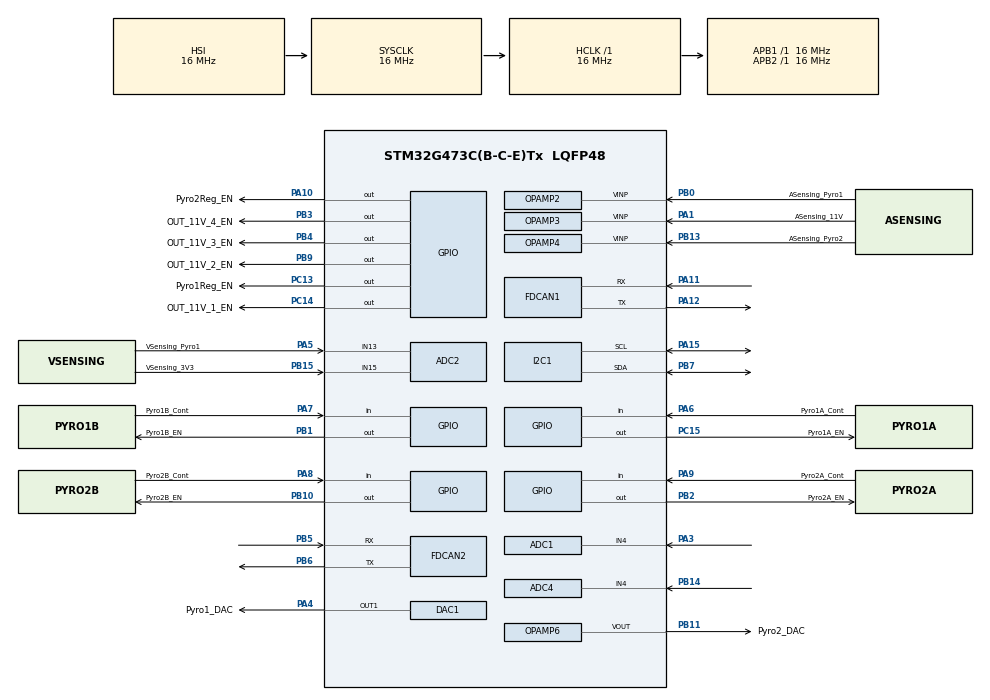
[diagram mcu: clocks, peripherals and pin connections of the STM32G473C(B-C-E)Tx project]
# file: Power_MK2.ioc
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ADC1.Channel-0\#ChannelRegularConversion=ADC_CHANNEL_4
ADC1.NbrOfConversion=1
ADC1.NbrOfConversionFlag=1
ADC1.OffsetNumber-0\#ChannelRegularConversion=ADC_OFFSET_NONE
ADC1.Rank-0\#ChannelRegularConversion=1
ADC1.SamplingTime-0\#ChannelRegularConversion=ADC_SAMPLETIME_2CYCLES_5
ADC1.master=1
ADC2.Channel-0\#ChannelRegularConversion=ADC_CHANNEL_13
ADC2.NbrOfConversionFlag=1
ADC2.OffsetNumber-0\#ChannelRegularConversion=ADC_OFFSET_NONE
ADC2.Rank-0\#ChannelRegularConversion=1
ADC2.SamplingTime-0\#ChannelRegularConversion=ADC_SAMPLETIME_2CYCLES_5
ADC4.Channel-2\#ChannelRegularConversion=ADC_CHANNEL_4
ADC4.NbrOfConversionFlag=1
ADC4.OffsetNumber-2\#ChannelRegularConversion=ADC_OFFSET_NONE
ADC4.Rank-2\#ChannelRegularConversion=1
ADC4.SamplingTime-2\#ChannelRegularConversion=ADC_SAMPLETIME_2CYCLES_5
FDCAN1.AutoRetransmission=ENABLE
FDCAN1.CalculateBaudRateNominal=1000000
FDCAN1.CalculateTimeBitNominal=1000
FDCAN1.CalculateTimeQuantumNominal=62.5
FDCAN1.FrameFormat=FDCAN_FRAME_FD_NO_BRS
FDCAN1.NominalPrescaler=2
FDCAN1.NominalSyncJumpWidth=2
FDCAN1.NominalTimeSeg1=13
FDCAN1.NominalTimeSeg2=2
FDCAN1.StdFiltersNbr=1
FDCAN2.AutoRetransmission=ENABLE
FDCAN2.CalculateBaudRateNominal=1000000
FDCAN2.CalculateTimeBitNominal=1000
FDCAN2.CalculateTimeQuantumNominal=62.5
FDCAN2.FrameFormat=FDCAN_FRAME_FD_NO_BRS
FDCAN2.NominalPrescaler=2
FDCAN2.NominalSyncJumpWidth=2
FDCAN2.NominalTimeSeg1=13
FDCAN2.NominalTimeSeg2=2
FDCAN2.StdFiltersNbr=1
I2C1.Timing=0x00503D58
Mcu.Family=STM32G4
Mcu.Name=STM32G473C(B-C-E)Tx
Mcu.Package=LQFP48
NVIC.PriorityGroup=NVIC_PRIORITYGROUP_4
PA1.GPIO_Label=ASensing_11V
PA1.Mode=Follower_Internally_Connected
PA1.Signal=OPAMP3_VINP
PA10.GPIO_Label=Pyro2Reg_EN
PA10.Signal=GPIO_Output
PA11.Mode=FDCAN_Activate
PA11.Signal=FDCAN1_RX
PA12.Mode=FDCAN_Activate
PA12.Signal=FDCAN1_TX
PA13.Mode=Serial_Wire
PA13.Signal=SYS_JTMS-SWDIO
PA14.Mode=Serial_Wire
PA14.Signal=SYS_JTCK-SWCLK
PA15.Mode=I2C
PA15.Signal=I2C1_SCL
PA3.Mode=IN4-Single-Ended
PA3.Signal=ADC1_IN4
PA4.GPIO_Label=Pyro1_DAC
PA4.Signal=COMP_DAC11_group
PA5.GPIO_Label=VSensing_Pyro1
PA5.Mode=IN13-Single-Ended
PA5.Signal=ADC2_IN13
PA6.GPIO_Label=Pyro1A_Cont
PA6.Signal=GPIO_Input
PA7.GPIO_Label=Pyro1B_Cont
PA7.Signal=GPIO_Input
PA8.GPIO_Label=Pyro2B_Cont
PA8.Signal=GPIO_Input
PA9.GPIO_Label=Pyro2A_Cont
PA9.Signal=GPIO_Input
PB0.GPIO_Label=ASensing_Pyro1
PB0.Mode=Follower_Internally_Connected
PB0.Signal=OPAMP2_VINP
PB1.GPIO_Label=Pyro1B_EN
PB1.Signal=GPIO_Output
PB10.GPIO_Label=Pyro2B_EN
PB10.Signal=GPIO_Output
PB11.GPIO_Label=Pyro2_DAC
PB11.Mode=Follower-DAC_OUT2-INP
PB11.Signal=OPAMP6_VOUT
PB12.GPIO_Label=VSensing_Pyro2
PB12.Signal=ADC1_IN11
PB13.GPIO_Label=ASensing_Pyro2
PB13.Mode=Follower_Internally_Connected
PB13.Signal=OPAMP4_VINP
PB14.Mode=IN4-Single-Ended
PB14.Signal=ADC4_IN4
PB15.GPIO_Label=VSensing_3V3
PB15.Mode=IN15-Single-Ended
PB15.Signal=ADC2_IN15
PB2.GPIO_Label=Pyro2A_EN
PB2.Signal=GPIO_Output
PB3.GPIO_Label=OUT_11V_4_EN
PB3.Signal=GPIO_Output
PB4.GPIO_Label=OUT_11V_3_EN
PB4.Signal=GPIO_Output
PB5.GPIO_Mode=GPIO_MODE_AF_PP
PB5.GPIO_PuPd=GPIO_NOPULL
PB5.GPIO_Speed=GPIO_SPEED_FREQ_LOW
PB5.Mode=FDCAN_Activate
PB5.Signal=FDCAN2_RX
PB6.GPIO_FM6=__NULL
PB6.GPIO_Mode=GPIO_MODE_AF_PP
PB6.GPIO_PuPd=GPIO_NOPULL
PB6.GPIO_Speed=GPIO_SPEED_FREQ_LOW
PB6.Mode=FDCAN_Activate
PB6.Signal=FDCAN2_TX
PB7.Mode=I2C
PB7.Signal=I2C1_SDA
PB9.GPIO_Label=OUT_11V_2_EN
PB9.Signal=GPIO_Output
PC13.GPIO_Label=Pyro1Reg_EN
PC13.Signal=GPIO_Output
PC14-OSC32_IN.GPIO_Label=OUT_11V_1_EN
PC14-OSC32_IN.Signal=GPIO_Output
PC15-OSC32_OUT.GPIO_Label=Pyro1A_EN
PC15-OSC32_OUT.Signal=GPIO_Output
PF0-OSC_IN.Mode=HSE-External-Oscillator
PF0-OSC_IN.Signal=RCC_OSC_IN
PF1-OSC_OUT.Mode=HSE-External-Oscillator
PF1-OSC_OUT.Signal=RCC_OSC_OUT
ProjectManager.HeapSize=0x200
ProjectManager.StackSize=0x400
ProjectManager.TargetToolchain=CMake
RCC.AHBFreq_Value=16000000
RCC.APB1Freq_Value=16000000
RCC.APB1TimFreq_Value=16000000
RCC.APB2Freq_Value=16000000
RCC.APB2TimFreq_Value=16000000
RCC.CortexFreq_Value=16000000
RCC.EXTERNAL_CLOCK_VALUE=12288000
RCC.FDCANCLockSelection=RCC_FDCANCLKSOURCE_PLL
RCC.HCLKFreq_Value=16000000
RCC.HSI48_VALUE=48000000
RCC.HSI_VALUE=16000000
RCC.LSE_VALUE=32768
RCC.PLLQ=RCC_PLLQ_DIV4
RCC.SYSCLKFreq_VALUE=16000000
RCC.USBFreq_Value=32000000
RCC.VCOOutputFreq_Value=128000000
SH.COMP_DAC11_group.0=DAC1_OUT1,DAC_OUT1
VP_DAC3_VS_DACI1.Mode=DAC_OUT1_Int
VP_SYS_VS_DBSignals.Mode=DisableDeadBatterySignals
board=custom

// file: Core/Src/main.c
/* USER CODE BEGIN Header */
/**
  ******************************************************************************
  * @file           : main.c
  * @brief          : Main program body
  ******************************************************************************
  * @attention
  *
  * Copyright (c) 2026 STMicroelectronics.
  * All rights reserved.
  *
  * This software is licensed under terms that can be found in the LICENSE file
  * in the root directory of this software component.
  * If no LICENSE file comes with this software, it is provided AS-IS.
  *
  ******************************************************************************
  */
/* USER CODE END Header */
#include "main.h"
#include "adc.h"
#include "dac.h"
#include "fdcan.h"
#include "i2c.h"
#include "opamp.h"
#include "gpio.h"

/* USER CODE BEGIN Includes */

#include "stm32g4xx_hal_gpio.h"
#include "canNode.h"
#include "pyro.h"
#include "power_monitor.h"
#include "pyro_control.h"
#include "sys_init.h"

/* USER CODE END Includes */

void SystemClock_Config(void);

int main(void)
{

  /* MCU Configuration--------------------------------------------------------*/

  /* Reset of all peripherals, Initializes the Flash interface and the Systick. */
  HAL_Init();

  /* Configure the system clock */
  SystemClock_Config();

  /* Initialize all configured peripherals */
  MX_GPIO_Init();
  MX_ADC1_Init();
  MX_ADC2_Init();
  MX_DAC1_Init();
  MX_DAC3_Init();
  MX_FDCAN1_Init();
  MX_FDCAN2_Init();
  MX_I2C1_Init();
  MX_OPAMP2_Init();
  MX_OPAMP3_Init();
  MX_OPAMP4_Init();
  MX_OPAMP6_Init();
  MX_ADC4_Init();
  /* USER CODE BEGIN 2 */

  Sys_init();

  while(!CanNode_PollWakeUp()) {} // espera a que le llegue el wake up

  AllPyroCheck();

  Pyro1_ON(); // encendemos la alimentacion de los pyrotecnicos
  Pyro2_ON();

  /* USER CODE END 2 */

  /* Infinite loop */
  while (1)
  {

    /* USER CODE BEGIN 3 */
    CanNode_Poll();       // lee CAN1: wake up y comandos de pirotecnia (ICD, 6)
    PyroControl_Update(); // enciende, mide continuidad y apaga los pirotécnicos
    PowerMonitor_Update(); // responde a CMD_POWER_RAILS con tensiones y corrientes

  }
  /* USER CODE END 3 */
}

void SystemClock_Config(void)
{
  RCC_OscInitTypeDef RCC_OscInitStruct = {0};
  RCC_ClkInitTypeDef RCC_ClkInitStruct = {0};

  /** Configure the main internal regulator output voltage
  */
  HAL_PWREx_ControlVoltageScaling(PWR_REGULATOR_VOLTAGE_SCALE1);

  /** Initializes the RCC Oscillators according to the specified parameters
  * in the RCC_OscInitTypeDef structure.
  */
  RCC_OscInitStruct.OscillatorType = RCC_OSCILLATORTYPE_HSI;
  RCC_OscInitStruct.HSIState = RCC_HSI_ON;
  RCC_OscInitStruct.HSICalibrationValue = RCC_HSICALIBRATION_DEFAULT;
  RCC_OscInitStruct.PLL.PLLState = RCC_PLL_ON;
  RCC_OscInitStruct.PLL.PLLSource = RCC_PLLSOURCE_HSI;
  RCC_OscInitStruct.PLL.PLLM = RCC_PLLM_DIV1;
  RCC_OscInitStruct.PLL.PLLN = 8;
  RCC_OscInitStruct.PLL.PLLP = RCC_PLLP_DIV2;
  RCC_OscInitStruct.PLL.PLLQ = RCC_PLLQ_DIV4;
  RCC_OscInitStruct.PLL.PLLR = RCC_PLLR_DIV2;
  if (HAL_RCC_OscConfig(&RCC_OscInitStruct) != HAL_OK)
  {
    Error_Handler();
  }

  /** Initializes the CPU, AHB and APB buses clocks
  */
  RCC_ClkInitStruct.ClockType = RCC_CLOCKTYPE_HCLK|RCC_CLOCKTYPE_SYSCLK
                              |RCC_CLOCKTYPE_PCLK1|RCC_CLOCKTYPE_PCLK2;
  RCC_ClkInitStruct.SYSCLKSource = RCC_SYSCLKSOURCE_HSI;
  RCC_ClkInitStruct.AHBCLKDivider = RCC_SYSCLK_DIV1;
  RCC_ClkInitStruct.APB1CLKDivider = RCC_HCLK_DIV1;
  RCC_ClkInitStruct.APB2CLKDivider = RCC_HCLK_DIV1;

  if (HAL_RCC_ClockConfig(&RCC_ClkInitStruct, FLASH_LATENCY_0) != HAL_OK)
  {
    Error_Handler();
  }
}

void Error_Handler(void)
{
  __disable_irq();
  while (1)
  {
  }
}
